# DMASS_DTHE_DMASS_DTHE_DTHE_DTHE_CFG_DTHE_REGS_WRAP_VBUSP_TOP_40800000h register map
Vendor: Texas Instruments
Peripheral module from a debugger description file (folder am62L).
Registers are 32-bit, read-only, reset 0x0 unless marked. A register's access mark holds for its fields unless they carry their own. Offsets are as the file gives them; lines under a group give offsets from that group; [hi:lo] are bit positions; {n}, {i} and the like mark numbered series; 'fields as' and 'values as' point back to an identical list; <NAME> marks a mode.

## DMASS_DTHE_DTHE_DTHE_CFG_DTHE_REGS_WRAP_VBUSP_TOP
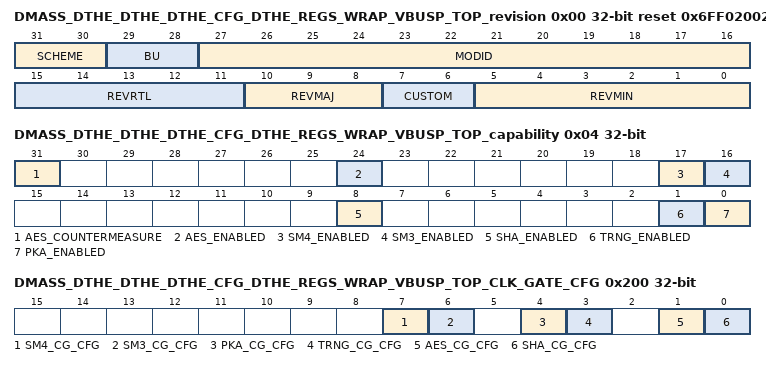
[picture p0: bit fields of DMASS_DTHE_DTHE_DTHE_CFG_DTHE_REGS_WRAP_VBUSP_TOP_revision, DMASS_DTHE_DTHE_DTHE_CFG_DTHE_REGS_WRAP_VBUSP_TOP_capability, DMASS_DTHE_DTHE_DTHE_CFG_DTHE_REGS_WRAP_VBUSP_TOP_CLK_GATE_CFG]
0x00 DMASS_DTHE_DTHE_DTHE_CFG_DTHE_REGS_WRAP_VBUSP_TOP_revision reset 0x6FF02002 — Version and Identification Register
  [31:30] SCHEME
  [29:28] BU — Business Unit
  [27:16] MODID — Module ID
  [15:11] REVRTL — RTL revision
  [10:8] REVMAJ — Major revision
  [7:6] CUSTOM — Custom revision
  [5:0] REVMIN — Minor Revision
0x04 DMASS_DTHE_DTHE_DTHE_CFG_DTHE_REGS_WRAP_VBUSP_TOP_capability — Capability register that reflects the efuse input on DTHE
  [31] AES_COUNTERMEASURE — aes countermeasure enabled
  [24] AES_ENABLED — aes core enabled
  [17] SM4_ENABLED — sm4 core enabled
  [16] SM3_ENABLED — sm3 core enabled
  [8] SHA_ENABLED — sha core enabled
  [1] TRNG_ENABLED — trng core enabled
  [0] PKA_ENABLED — pka core enabled
0x200 DMASS_DTHE_DTHE_DTHE_CFG_DTHE_REGS_WRAP_VBUSP_TOP_CLK_GATE_CFG rw — Write-only register to request clock gating of the individual crypto IP
  [7] SM4_CG_CFG — 0:request to un-gate. 1:request to gate the clock.
  [6] SM3_CG_CFG — 0:request to un-gate. 1:request to gate the clock.
  [4] PKA_CG_CFG — 0:request to un-gate. 1:request to gate the clock.
  [3] TRNG_CG_CFG — 0:request to un-gate. 1:request to gate the clock.
  [1] AES_CG_CFG — 0:request to un-gate. 1:request to gate the clock.
  [0] SHA_CG_CFG — 0:request to un-gate. 1:request to gate the clock.
